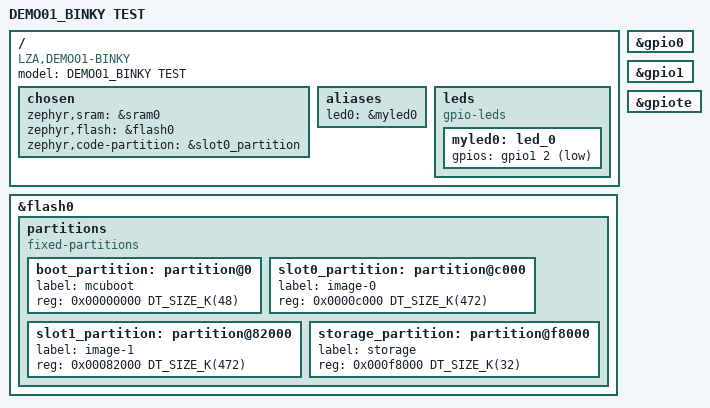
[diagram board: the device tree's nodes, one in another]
/dts-v1/;
#include <nordic/nrf52840_qiaa.dtsi>
#include "DEMO01_BINKY-pinctrl.dtsi"

/ {
	model = "DEMO01_BINKY TEST";
	compatible = "LZA,DEMO01-BINKY";

	chosen {
		zephyr,sram = &sram0;
		zephyr,flash = &flash0;
		zephyr,code-partition = &slot0_partition;
	};
		// LED
	aliases {
        led0 = &myled0;
     };

  	leds {
    	compatible = "gpio-leds";

		// GPIO 1.02 拉低有效
    	myled0: led_0 {
      		gpios = <&gpio1 2 GPIO_ACTIVE_LOW>;
    	};
  	};
};

&flash0 {
	partitions {
		compatible = "fixed-partitions";
		#address-cells = <1>;
		#size-cells = <1>;

		boot_partition: partition@0 {
			label = "mcuboot";
			reg = <0x00000000 DT_SIZE_K(48)>;
		};

		slot0_partition: partition@c000 {
			label = "image-0";
			reg = <0x0000c000 DT_SIZE_K(472)>;
		};

		slot1_partition: partition@82000 {
			label = "image-1";
			reg = <0x00082000 DT_SIZE_K(472)>;
		};

		storage_partition: partition@f8000 {
			label = "storage";
			reg = <0x000f8000 DT_SIZE_K(32)>;
		};
	};
};

// 开启GPIO外设
&gpio0 {
	status = "okay";
};

&gpio1 {
	status = "okay";
};

&gpiote {
	status = "okay";
};
